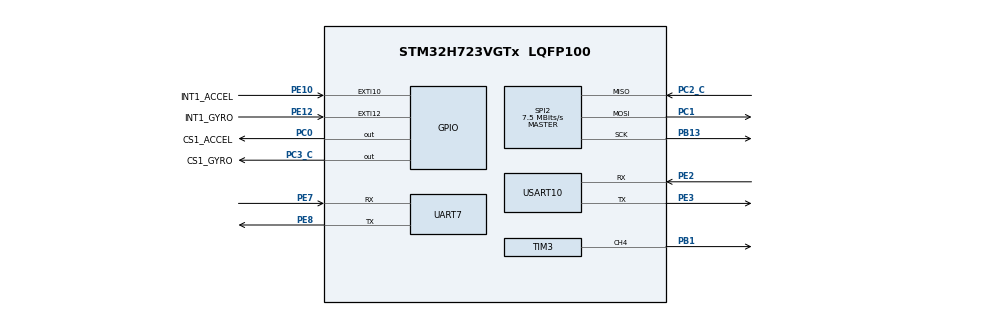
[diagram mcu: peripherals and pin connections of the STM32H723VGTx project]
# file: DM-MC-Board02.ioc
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CORTEX_M7.CPU_DCache=Enabled
CORTEX_M7.CPU_ICache=Enabled
CORTEX_M7.MPU_Control=__NULL
CORTEX_M7.default_mode_Activation=1
Dma.Request0=UART7_TX
Dma.UART7_TX.0.Direction=DMA_MEMORY_TO_PERIPH
Dma.UART7_TX.0.EventEnable=DISABLE
Dma.UART7_TX.0.FIFOMode=DMA_FIFOMODE_DISABLE
Dma.UART7_TX.0.Instance=DMA1_Stream1
Dma.UART7_TX.0.MemDataAlignment=DMA_MDATAALIGN_BYTE
Dma.UART7_TX.0.MemInc=DMA_MINC_ENABLE
Dma.UART7_TX.0.Mode=DMA_NORMAL
Dma.UART7_TX.0.PeriphDataAlignment=DMA_PDATAALIGN_BYTE
Dma.UART7_TX.0.PeriphInc=DMA_PINC_DISABLE
Dma.UART7_TX.0.Polarity=HAL_DMAMUX_REQ_GEN_RISING
Dma.UART7_TX.0.Priority=DMA_PRIORITY_LOW
Dma.UART7_TX.0.RequestNumber=1
Dma.UART7_TX.0.SignalID=NONE
Dma.UART7_TX.0.SyncEnable=DISABLE
Dma.UART7_TX.0.SyncPolarity=HAL_DMAMUX_SYNC_NO_EVENT
Dma.UART7_TX.0.SyncRequestNumber=1
Dma.UART7_TX.0.SyncSignalID=NONE
Mcu.Family=STM32H7
Mcu.Name=STM32H723VGTx
Mcu.Package=LQFP100
NVIC.DMA1_Stream1_IRQn=true\:7\:0\:true\:false\:true\:false\:true\:true
NVIC.PriorityGroup=NVIC_PRIORITYGROUP_4
NVIC.TIM5_IRQn=true\:0\:0\:false\:false\:false\:true\:false\:false
NVIC.TIM7_IRQn=true\:0\:0\:true\:false\:true\:false\:true\:true
NVIC.TimeBase=TIM7_IRQn
NVIC.TimeBaseIP=TIM7
NVIC.UART7_IRQn=true\:7\:0\:true\:false\:true\:true\:true\:true
PA13(JTMS/SWDIO).Mode=Serial_Wire
PA13(JTMS/SWDIO).Signal=DEBUG_JTMS-SWDIO
PA14(JTCK/SWCLK).Mode=Serial_Wire
PA14(JTCK/SWCLK).Signal=DEBUG_JTCK-SWCLK
PB1.Signal=S_TIM3_CH4
PB13.Mode=Full_Duplex_Master
PB13.Signal=SPI2_SCK
PC0.GPIO_Label=CS1_ACCEL
PC0.GPIO_PuPd=GPIO_PULLUP
PC0.GPIO_Speed=GPIO_SPEED_FREQ_HIGH
PC0.PinState=GPIO_PIN_SET
PC0.Signal=GPIO_Output
PC1.Mode=Full_Duplex_Master
PC1.Signal=SPI2_MOSI
PC2_C.Mode=Full_Duplex_Master
PC2_C.Signal=SPI2_MISO
PC3_C.GPIO_Label=CS1_GYRO
PC3_C.GPIO_PuPd=GPIO_PULLUP
PC3_C.GPIO_Speed=GPIO_SPEED_FREQ_HIGH
PC3_C.PinState=GPIO_PIN_SET
PC3_C.Signal=GPIO_Output
PE10.GPIO_Label=INT1_ACCEL
PE10.GPIO_ModeDefaultEXTI=GPIO_MODE_IT_FALLING
PE10.GPIO_PuPd=GPIO_PULLUP
PE10.Signal=GPXTI10
PE12.GPIO_Label=INT1_GYRO
PE12.GPIO_ModeDefaultEXTI=GPIO_MODE_IT_FALLING
PE12.GPIO_PuPd=GPIO_PULLUP
PE12.Signal=GPXTI12
PE2.Mode=Asynchronous
PE2.Signal=USART10_RX
PE3.Mode=Asynchronous
PE3.Signal=USART10_TX
PE7.Mode=Asynchronous
PE7.Signal=UART7_RX
PE8.Mode=Asynchronous
PE8.Signal=UART7_TX
PH0-OSC_IN.Mode=HSE-External-Oscillator
PH0-OSC_IN.Signal=RCC_OSC_IN
PH1-OSC_OUT.Mode=HSE-External-Oscillator
PH1-OSC_OUT.Signal=RCC_OSC_OUT
ProjectManager.HeapSize=0x200
ProjectManager.StackSize=0x400
ProjectManager.TargetToolchain=CMake
RCC.ADCFreq_Value=48375000
RCC.APB1Freq_Value=120000000
RCC.APB2Freq_Value=120000000
RCC.APB3Freq_Value=120000000
RCC.APB4Freq_Value=120000000
RCC.CortexFreq_Value=480000000
RCC.D1PPRE=RCC_APB3_DIV2
RCC.D2PPRE1=RCC_APB1_DIV2
RCC.D2PPRE2=RCC_APB2_DIV2
RCC.D3PPRE=RCC_APB4_DIV2
RCC.DIVM1=2
RCC.DIVN1=40
RCC.DIVP1=1
RCC.DIVQ1=4
RCC.HCLKFreq_Value=240000000
RCC.HPRE=RCC_HCLK_DIV2
RCC.HSE_VALUE=24000000
RCC.PLL2FRACN=0
RCC.PLL3FRACN=0
RCC.PLLFRACN=0
RCC.PLLSourceVirtual=RCC_PLLSOURCE_HSE
RCC.SYSCLKFreq_VALUE=480000000
RCC.SYSCLKSource=RCC_SYSCLKSOURCE_PLLCLK
RCC.USBFreq_Value=120000000
SH.S_TIM3_CH4.0=TIM3_CH4,PWM Generation4 CH4
SPI2.BaudRatePrescaler=SPI_BAUDRATEPRESCALER_16
SPI2.CLKPhase=SPI_PHASE_2EDGE
SPI2.CLKPolarity=SPI_POLARITY_HIGH
SPI2.CalculateBaudRate=7.5 MBits/s
SPI2.DataSize=SPI_DATASIZE_8BIT
SPI2.Direction=SPI_DIRECTION_2LINES
SPI2.Mode=SPI_MODE_MASTER
SPI2.NSSPMode=SPI_NSS_PULSE_DISABLE
SPI2.VirtualType=VM_MASTER
TIM3.Channel-PWM\ Generation4\ CH4=TIM_CHANNEL_4
TIM3.Period=20000 - 1
TIM3.Prescaler=240 - 1
TIM5.Period=0xFFFFFFFFU - 1U
TIM5.Prescaler=240 - 1
USART10.VirtualMode=VM_ASYNC
VP_MEMORYMAP_VS_MEMORYMAP.Mode=CurAppReg
VP_SYS_VS_tim7.Mode=TIM7
VP_TIM5_VS_ClockSourceINT.Mode=Internal
board=custom

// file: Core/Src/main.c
/* USER CODE BEGIN Header */
/**
  ******************************************************************************
  * @file           : main.c
  * @brief          : Main program body
  ******************************************************************************
  * @attention
  *
  * Copyright (c) 2025 STMicroelectronics.
  * All rights reserved.
  *
  * This software is licensed under terms that can be found in the LICENSE file
  * in the root directory of this software component.
  * If no LICENSE file comes with this software, it is provided AS-IS.
  *
  ******************************************************************************
  */
/* USER CODE END Header */
#include "main.h"
#include "dma.h"
#include "spi.h"
#include "tim.h"
#include "usart.h"
#include "gpio.h"

/* USER CODE BEGIN Includes */

#include "rmdev_test.h"

#include "emdevif/core/fatal_handler.h"

/* USER CODE END Includes */

void SystemClock_Config(void);

int main(void)
{

  /* USER CODE BEGIN 1 */

  testInit(NULL);

  /* USER CODE END 1 */

  /* Enable the CPU Cache */

  /* Enable I-Cache---------------------------------------------------------*/
  SCB_EnableICache();

  /* Enable D-Cache---------------------------------------------------------*/
  SCB_EnableDCache();

  /* MCU Configuration--------------------------------------------------------*/

  /* Reset of all peripherals, Initializes the Flash interface and the Systick. */
  HAL_Init();

  /* Configure the system clock */
  SystemClock_Config();

  /* Initialize all configured peripherals */
  MX_GPIO_Init();
  MX_DMA_Init();
  MX_SPI2_Init();
  MX_TIM5_Init();
  MX_UART7_Init();
  MX_USART10_UART_Init();
  MX_TIM3_Init();
  /* USER CODE BEGIN 2 */

  LL_TIM_DisableCounter(TIM5);
  LL_TIM_SetCounter(TIM5, 0U);
  LL_TIM_ClearFlag_UPDATE(TIM5);
  LL_TIM_EnableIT_UPDATE(TIM5);
  LL_TIM_EnableCounter(TIM5);

  testEntry();

  /* USER CODE END 2 */

  /* Infinite loop */
  while (1)
  {

  }
}

void SystemClock_Config(void)
{
  RCC_OscInitTypeDef RCC_OscInitStruct = {0};
  RCC_ClkInitTypeDef RCC_ClkInitStruct = {0};

  /** Supply configuration update enable
  */
  HAL_PWREx_ConfigSupply(PWR_LDO_SUPPLY);

  /** Configure the main internal regulator output voltage
  */
  __HAL_PWR_VOLTAGESCALING_CONFIG(PWR_REGULATOR_VOLTAGE_SCALE0);

  while(!__HAL_PWR_GET_FLAG(PWR_FLAG_VOSRDY)) {}

  /** Initializes the RCC Oscillators according to the specified parameters
  * in the RCC_OscInitTypeDef structure.
  */
  RCC_OscInitStruct.OscillatorType = RCC_OSCILLATORTYPE_HSE;
  RCC_OscInitStruct.HSEState = RCC_HSE_ON;
  RCC_OscInitStruct.PLL.PLLState = RCC_PLL_ON;
  RCC_OscInitStruct.PLL.PLLSource = RCC_PLLSOURCE_HSE;
  RCC_OscInitStruct.PLL.PLLM = 2;
  RCC_OscInitStruct.PLL.PLLN = 40;
  RCC_OscInitStruct.PLL.PLLP = 1;
  RCC_OscInitStruct.PLL.PLLQ = 4;
  RCC_OscInitStruct.PLL.PLLR = 2;
  RCC_OscInitStruct.PLL.PLLRGE = RCC_PLL1VCIRANGE_3;
  RCC_OscInitStruct.PLL.PLLVCOSEL = RCC_PLL1VCOWIDE;
  RCC_OscInitStruct.PLL.PLLFRACN = 0;
  if (HAL_RCC_OscConfig(&RCC_OscInitStruct) != HAL_OK)
  {
    Error_Handler();
  }

  /** Initializes the CPU, AHB and APB buses clocks
  */
  RCC_ClkInitStruct.ClockType = RCC_CLOCKTYPE_HCLK|RCC_CLOCKTYPE_SYSCLK
                              |RCC_CLOCKTYPE_PCLK1|RCC_CLOCKTYPE_PCLK2
                              |RCC_CLOCKTYPE_D3PCLK1|RCC_CLOCKTYPE_D1PCLK1;
  RCC_ClkInitStruct.SYSCLKSource = RCC_SYSCLKSOURCE_PLLCLK;
  RCC_ClkInitStruct.SYSCLKDivider = RCC_SYSCLK_DIV1;
  RCC_ClkInitStruct.AHBCLKDivider = RCC_HCLK_DIV2;
  RCC_ClkInitStruct.APB3CLKDivider = RCC_APB3_DIV2;
  RCC_ClkInitStruct.APB1CLKDivider = RCC_APB1_DIV2;
  RCC_ClkInitStruct.APB2CLKDivider = RCC_APB2_DIV2;
  RCC_ClkInitStruct.APB4CLKDivider = RCC_APB4_DIV2;

  if (HAL_RCC_ClockConfig(&RCC_ClkInitStruct, FLASH_LATENCY_3) != HAL_OK)
  {
    Error_Handler();
  }
}

void HAL_TIM_PeriodElapsedCallback(TIM_HandleTypeDef *htim)
{
  if (htim->Instance == TIM7)
  {
    HAL_IncTick();
  }
}

void Error_Handler(void)
{
  /* USER CODE BEGIN Error_Handler_Debug */
  /* User can add his own implementation to report the HAL error return state */

  EMDEVIF_FATAL_HANDLER("Error_Handler called.");

  /* USER CODE END Error_Handler_Debug */
}
#ifdef USE_FULL_ASSERT
/**
  * @brief  Reports the name of the source file and the source line number
  *         where the assert_param error has occurred.
  * @param  file: pointer to the source file name
  * @param  line: assert_param error line source number
  * @retval None
  */
void assert_failed(uint8_t *file, uint32_t line)
{
  /* USER CODE BEGIN 6 */
  /* User can add his own implementation to report the file name and line number,
     ex: printf("Wrong parameters value: file %s on line %d\r\n", file, line) */

  EMDEVIF_FATAL_HANDLER("STM32 assert_param failed.");

  /* USER CODE END 6 */
}
#endif /* USE_FULL_ASSERT */
